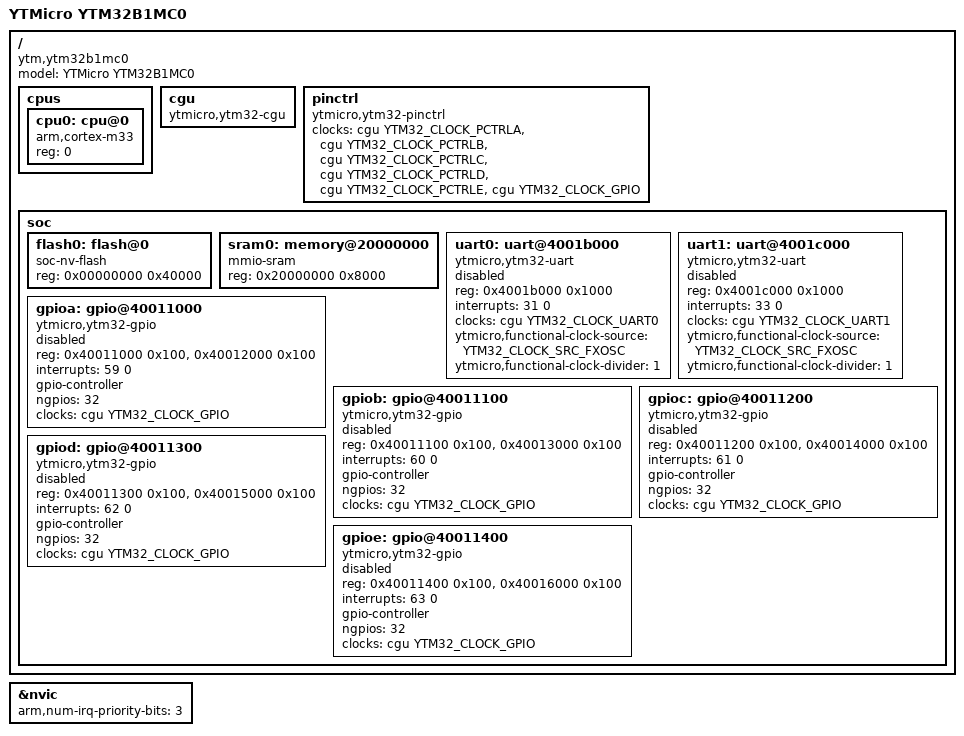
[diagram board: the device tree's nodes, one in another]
/*
 * Copyright (c) 2026 YI JIN <jinyi_2001@foxmail.com>
 * SPDX-License-Identifier: Apache-2.0
 */

#include <arm/armv8-m.dtsi>
#include <zephyr/dt-bindings/clock/ytmicro,ytm32-clock.h>

/ {
	model = "YTMicro YTM32B1MC0";
	compatible = "ytm,ytm32b1mc0";

	cpus {
		#address-cells = <1>;
		#size-cells = <0>;

		cpu0: cpu@0 {
			device_type = "cpu";
			compatible = "arm,cortex-m33";
			reg = <0>;
			#address-cells = <1>;
			#size-cells = <1>;
		};
	};

	cgu: cgu {
		compatible = "ytmicro,ytm32-cgu";
		#clock-cells = <1>;
		status = "okay";
	};

	pinctrl: pinctrl {
		compatible = "ytmicro,ytm32-pinctrl";
		clocks = <&cgu YTM32_CLOCK_PCTRLA>,
			 <&cgu YTM32_CLOCK_PCTRLB>,
			 <&cgu YTM32_CLOCK_PCTRLC>,
			 <&cgu YTM32_CLOCK_PCTRLD>,
			 <&cgu YTM32_CLOCK_PCTRLE>,
			 <&cgu YTM32_CLOCK_GPIO>;
		status = "okay";
	};

	soc {
		flash0: flash@0 {
			compatible = "soc-nv-flash";
			reg = <0x00000000 0x40000>;
		};

		sram0: memory@20000000 {
			compatible = "mmio-sram";
			reg = <0x20000000 0x8000>;
		};

		uart0: uart@4001b000 { 
			compatible = "ytmicro,ytm32-uart";
			reg = <0x4001b000 0x1000>;
			interrupts = <31 0>;
			clocks = <&cgu YTM32_CLOCK_UART0>;
			ytmicro,functional-clock-source = <YTM32_CLOCK_SRC_FXOSC>;
			ytmicro,functional-clock-divider = <1>;
			status = "disabled";
		};

		uart1: uart@4001c000 { 
			compatible = "ytmicro,ytm32-uart";
			reg = <0x4001c000 0x1000>;
			interrupts = <33 0>; 
			clocks = <&cgu YTM32_CLOCK_UART1>;
			ytmicro,functional-clock-source = <YTM32_CLOCK_SRC_FXOSC>;
			ytmicro,functional-clock-divider = <1>;
			status = "disabled";
		};

		gpioa: gpio@40011000 {
			compatible = "ytmicro,ytm32-gpio";
			reg = <0x40011000 0x100>,  /* GPIO */
			      <0x40012000 0x100>;  /* PCTRLA */
			reg-names = "gpio", "pctrl";
			interrupts = <59 0>;
			gpio-controller;
			#gpio-cells = <2>;
			ngpios = <32>;
			clocks = <&cgu YTM32_CLOCK_GPIO>;
			status = "disabled";
		};

		gpiob: gpio@40011100 {
			compatible = "ytmicro,ytm32-gpio";
			reg = <0x40011100 0x100>,  /* GPIO */
			      <0x40013000 0x100>;  /* PCTRLB */
			reg-names = "gpio", "pctrl";
			interrupts = <60 0>;
			gpio-controller;
			#gpio-cells = <2>;
			ngpios = <32>;
			clocks = <&cgu YTM32_CLOCK_GPIO>;
			status = "disabled";
		};

		gpioc: gpio@40011200 {
			compatible = "ytmicro,ytm32-gpio";
			reg = <0x40011200 0x100>,  /* GPIO */
			      <0x40014000 0x100>;  /* PCTRLC */
			reg-names = "gpio", "pctrl";
			interrupts = <61 0>;
			gpio-controller;
			#gpio-cells = <2>;
			ngpios = <32>;
			clocks = <&cgu YTM32_CLOCK_GPIO>;
			status = "disabled";
		};

		gpiod: gpio@40011300 {
			compatible = "ytmicro,ytm32-gpio";
			reg = <0x40011300 0x100>,  /* GPIO */
			      <0x40015000 0x100>;  /* PCTRLD */
			reg-names = "gpio", "pctrl";
			interrupts = <62 0>;
			gpio-controller;
			#gpio-cells = <2>;
			ngpios = <32>;
			clocks = <&cgu YTM32_CLOCK_GPIO>;
			status = "disabled";
		};

		gpioe: gpio@40011400 {
			compatible = "ytmicro,ytm32-gpio";
			reg = <0x40011400 0x100>,  /* GPIO */
			      <0x40016000 0x100>;  /* PCTRLE */
			reg-names = "gpio", "pctrl";
			interrupts = <63 0>;
			gpio-controller;
			#gpio-cells = <2>;
			ngpios = <32>;
			clocks = <&cgu YTM32_CLOCK_GPIO>;
			status = "disabled";
		};

	};
};

&nvic {
	arm,num-irq-priority-bits = <3>;
};
